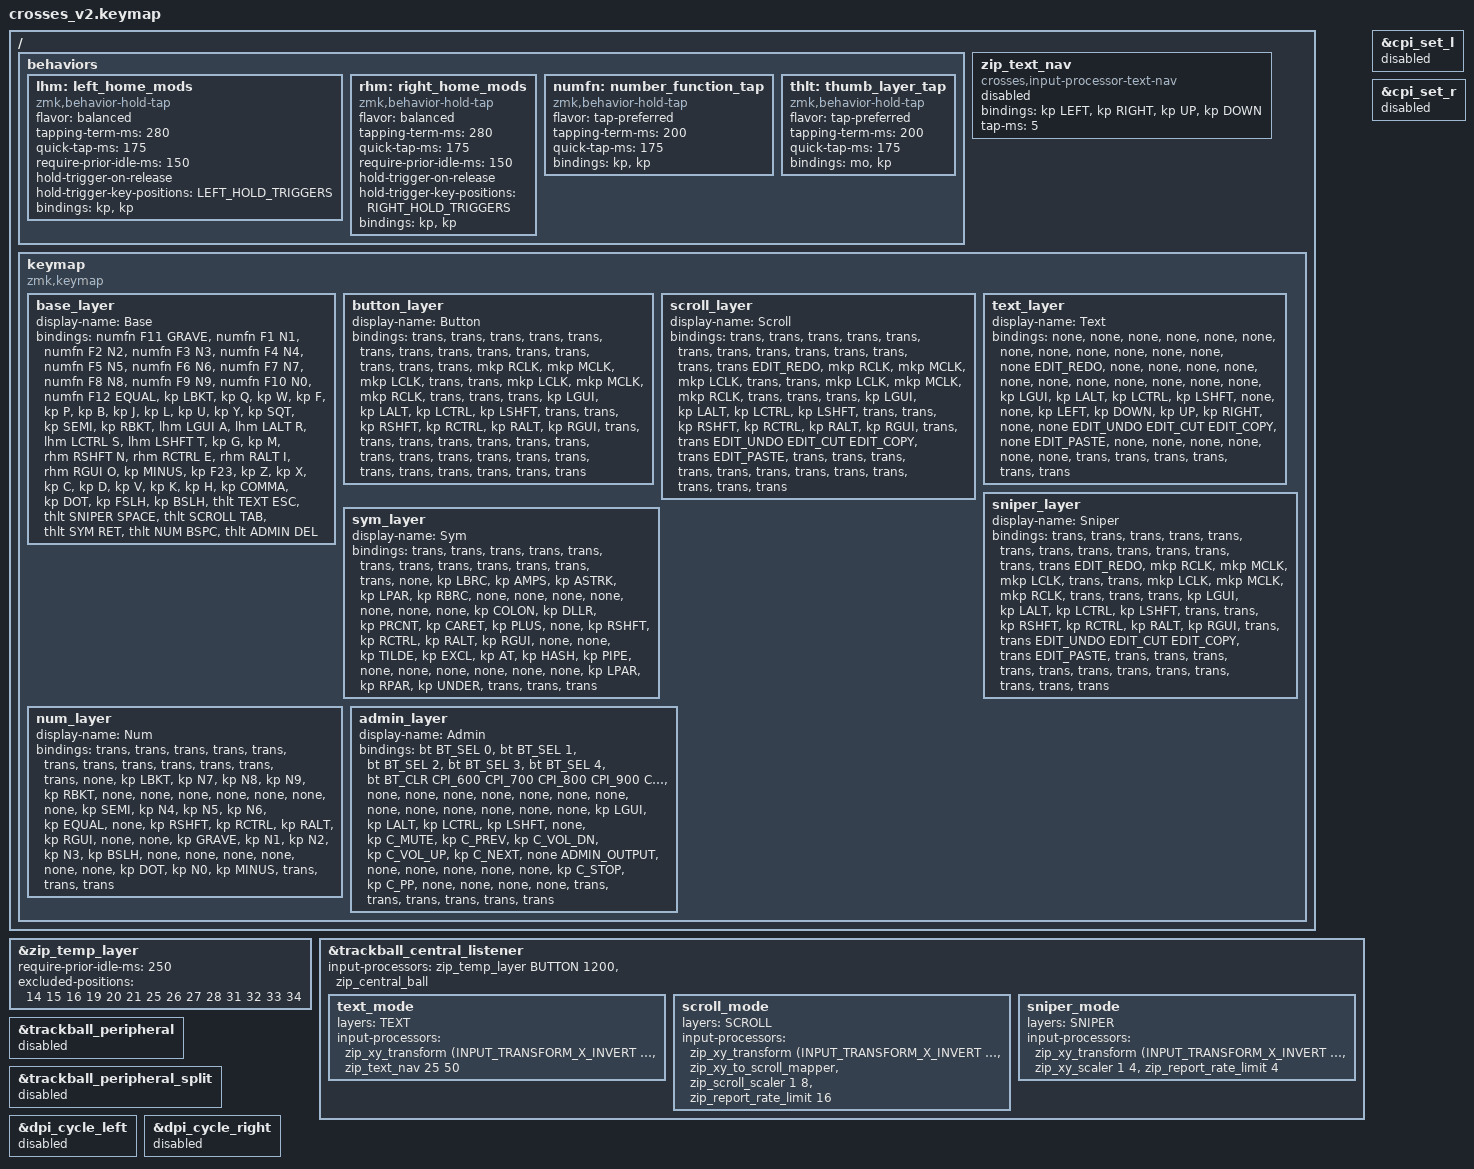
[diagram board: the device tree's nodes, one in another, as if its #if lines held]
#include <behaviors.dtsi>
#include <dt-bindings/zmk/bt.h>
#include <dt-bindings/zmk/input_transform.h>
#include <dt-bindings/zmk/keys.h>
#include <dt-bindings/zmk/outputs.h>
#include <dt-bindings/zmk/pointing.h>

/*
 * Physical positions (54-key layout):
 *   00-11  number row
 *   12-23  top alpha row
 *   24-35  home alpha row
 *   36-47  bottom alpha row
 *   48-53  thumbs
 */

#define BASE    0
#define BUTTON  1
#define SCROLL  2
#define TEXT    3
#define SNIPER  4
#define SYM     5
#define NUM     6
#define ADMIN   7

/* Opposite hand plus all six thumbs. */
#define LEFT_HOLD_TRIGGERS  6 7 8 9 10 11 18 19 20 21 22 23 30 31 32 33 34 35 42 43 44 45 46 47 48 49 50 51 52 53
#define RIGHT_HOLD_TRIGGERS 0 1 2 3 4 5 12 13 14 15 16 17 24 25 26 27 28 29 36 37 38 39 40 41 48 49 50 51 52 53

#define EDIT_REDO  &kp LC(Y)
#define EDIT_UNDO  &kp LC(Z)
#define EDIT_CUT   &kp LC(X)
#define EDIT_COPY  &kp LC(C)
#define EDIT_PASTE &kp LC(V)

/* CPI controls only exist on the right/central firmware. The corresponding
 * physical positions do not exist on the left half anyway. */
#if defined(CROSSES_RIGHT_CONFIG)
#define CPI_600  &cpi_set_r 608 1
#define CPI_700  &cpi_set_r 684 1
#define CPI_800  &cpi_set_r 798 1
#define CPI_900  &cpi_set_r 912 1
#define CPI_1000 &cpi_set_r 988 1
#define CPI_1200 &cpi_set_r 1216 1
#else
#define CPI_600  &none
#define CPI_700  &none
#define CPI_800  &none
#define CPI_900  &none
#define CPI_1000 &none
#define CPI_1200 &none
#endif

#if defined(CROSSES_RIGHT_CONFIG)
#define ADMIN_OUTPUT &out OUT_TOG
#else
#define ADMIN_OUTPUT &none
#endif

/ {
    behaviors {
        /* Urob-style "timeless" positional home-row mod-taps. */
        lhm: left_home_mods {
            compatible = "zmk,behavior-hold-tap";
            #binding-cells = <2>;
            flavor = "balanced";
            tapping-term-ms = <280>;
            quick-tap-ms = <175>;
            require-prior-idle-ms = <150>;
            hold-trigger-on-release;
            hold-trigger-key-positions = <LEFT_HOLD_TRIGGERS>;
            bindings = <&kp>, <&kp>;
        };

        rhm: right_home_mods {
            compatible = "zmk,behavior-hold-tap";
            #binding-cells = <2>;
            flavor = "balanced";
            tapping-term-ms = <280>;
            quick-tap-ms = <175>;
            require-prior-idle-ms = <150>;
            hold-trigger-on-release;
            hold-trigger-key-positions = <RIGHT_HOLD_TRIGGERS>;
            bindings = <&kp>, <&kp>;
        };

        /* Tap for a number-row key (and its shifted symbol), hold for F1-F12. */
        numfn: number_function_tap {
            compatible = "zmk,behavior-hold-tap";
            #binding-cells = <2>;
            flavor = "tap-preferred";
            tapping-term-ms = <200>;
            quick-tap-ms = <175>;
            bindings = <&kp>, <&kp>;
        };

        /* Layer-tap with tap-then-hold support for repeating Backspace/Delete. */
        thlt: thumb_layer_tap {
            compatible = "zmk,behavior-hold-tap";
            #binding-cells = <2>;
            flavor = "tap-preferred";
            tapping-term-ms = <200>;
            quick-tap-ms = <175>;
            bindings = <&mo>, <&kp>;
        };
    };

    /* Horizontal and vertical movement thresholds are passed separately. */
    zip_text_nav: zip_text_nav {
        compatible = "crosses,input-processor-text-nav";
        #input-processor-cells = <2>;
        bindings = <&kp LEFT>, <&kp RIGHT>, <&kp UP>, <&kp DOWN>;
        tap-ms = <5>;
    };

    keymap {
        compatible = "zmk,keymap";

        base_layer {
            display-name = "Base";
            bindings = <
                &numfn F11 GRAVE  &numfn F1 N1  &numfn F2 N2  &numfn F3 N3  &numfn F4 N4  &numfn F5 N5   &numfn F6 N6  &numfn F7 N7  &numfn F8 N8  &numfn F9 N9  &numfn F10 N0  &numfn F12 EQUAL
                &kp LBKT       &kp Q          &kp W          &kp F          &kp P          &kp B           &kp J          &kp L          &kp U          &kp Y           &kp SQT           &kp SEMI
                &kp RBKT       &lhm LGUI A    &lhm LALT R    &lhm LCTRL S   &lhm LSHFT T   &kp G           &kp M          &rhm RSHFT N   &rhm RCTRL E   &rhm RALT I     &rhm RGUI O       &kp MINUS
                &kp F23        &kp Z          &kp X          &kp C          &kp D          &kp V           &kp K          &kp H          &kp COMMA      &kp DOT         &kp FSLH          &kp BSLH
                                                &thlt TEXT ESC  &thlt SNIPER SPACE  &thlt SCROLL TAB   &thlt SYM RET  &thlt NUM BSPC  &thlt ADMIN DEL
            >;
        };

        /* Automatically active after ordinary cursor movement. */
        button_layer {
            display-name = "Button";
            bindings = <
                &trans &trans &trans &trans &trans &trans   &trans &trans &trans &trans &trans &trans
                &trans &trans &mkp RCLK &mkp MCLK &mkp LCLK &trans   &trans &mkp LCLK &mkp MCLK &mkp RCLK &trans &trans
                &trans &kp LGUI &kp LALT &kp LCTRL &kp LSHFT &trans   &trans &kp RSHFT &kp RCTRL &kp RALT &kp RGUI &trans
                &trans &trans &trans &trans &trans &trans   &trans &trans &trans &trans &trans &trans
                                  &trans &trans &trans   &trans &trans &trans
            >;
        };

        scroll_layer {
            display-name = "Scroll";
            bindings = <
                &trans &trans &trans &trans &trans &trans   &trans &trans &trans &trans &trans &trans
                &trans EDIT_REDO &mkp RCLK &mkp MCLK &mkp LCLK &trans   &trans &mkp LCLK &mkp MCLK &mkp RCLK &trans &trans
                &trans &kp LGUI &kp LALT &kp LCTRL &kp LSHFT &trans   &trans &kp RSHFT &kp RCTRL &kp RALT &kp RGUI &trans
                &trans EDIT_UNDO EDIT_CUT EDIT_COPY &trans EDIT_PASTE   &trans &trans &trans &trans &trans &trans
                                  &trans &trans &trans   &trans &trans &trans
            >;
        };

        text_layer {
            display-name = "Text";
            bindings = <
                &none &none &none &none &none &none   &none &none &none &none &none &none
                &none EDIT_REDO &none &none &none &none   &none &none &none &none &none &none
                &none &kp LGUI &kp LALT &kp LCTRL &kp LSHFT &none   &none &kp LEFT &kp DOWN &kp UP &kp RIGHT &none
                &none EDIT_UNDO EDIT_CUT EDIT_COPY &none EDIT_PASTE   &none &none &none &none &none &none
                                  &trans &trans &trans   &trans &trans &trans
            >;
        };

        sniper_layer {
            display-name = "Sniper";
            bindings = <
                &trans &trans &trans &trans &trans &trans   &trans &trans &trans &trans &trans &trans
                &trans EDIT_REDO &mkp RCLK &mkp MCLK &mkp LCLK &trans   &trans &mkp LCLK &mkp MCLK &mkp RCLK &trans &trans
                &trans &kp LGUI &kp LALT &kp LCTRL &kp LSHFT &trans   &trans &kp RSHFT &kp RCTRL &kp RALT &kp RGUI &trans
                &trans EDIT_UNDO EDIT_CUT EDIT_COPY &trans EDIT_PASTE   &trans &trans &trans &trans &trans &trans
                                  &trans &trans &trans   &trans &trans &trans
            >;
        };

        /* Stripped canonical Miryoku symbol core on the left 3x5. */
        sym_layer {
            display-name = "Sym";
            bindings = <
                &trans &trans &trans &trans &trans &trans   &trans &trans &trans &trans &trans &trans
                &none &kp LBRC &kp AMPS &kp ASTRK &kp LPAR &kp RBRC   &none &none &none &none &none &none
                &none &kp COLON &kp DLLR &kp PRCNT &kp CARET &kp PLUS   &none &kp RSHFT &kp RCTRL &kp RALT &kp RGUI &none
                &none &kp TILDE &kp EXCL &kp AT &kp HASH &kp PIPE   &none &none &none &none &none &none
                                  &kp LPAR &kp RPAR &kp UNDER   &trans &trans &trans
            >;
        };

        /* Stripped canonical Miryoku numeric keypad on the left 3x5. */
        num_layer {
            display-name = "Num";
            bindings = <
                &trans &trans &trans &trans &trans &trans   &trans &trans &trans &trans &trans &trans
                &none &kp LBKT &kp N7 &kp N8 &kp N9 &kp RBKT   &none &none &none &none &none &none
                &none &kp SEMI &kp N4 &kp N5 &kp N6 &kp EQUAL   &none &kp RSHFT &kp RCTRL &kp RALT &kp RGUI &none
                &none &kp GRAVE &kp N1 &kp N2 &kp N3 &kp BSLH   &none &none &none &none &none &none
                                  &kp DOT &kp N0 &kp MINUS   &trans &trans &trans
            >;
        };

        admin_layer {
            display-name = "Admin";
            bindings = <
                &bt BT_SEL 0  &bt BT_SEL 1  &bt BT_SEL 2  &bt BT_SEL 3  &bt BT_SEL 4  &bt BT_CLR   CPI_600 CPI_700 CPI_800 CPI_900 CPI_1000 CPI_1200
                &none &none &none &none &none &none   &none &none &none &none &none &none
                &none &kp LGUI &kp LALT &kp LCTRL &kp LSHFT &none   &kp C_MUTE &kp C_PREV &kp C_VOL_DN &kp C_VOL_UP &kp C_NEXT &none
                ADMIN_OUTPUT &none &none &none &none &none   &kp C_STOP &kp C_PP &none &none &none &none
                                  &trans &trans &trans   &trans &trans &trans
            >;
        };
    };
};

/* Automatic click layer while the default cursor pipeline is moving. */
&zip_temp_layer {
    require-prior-idle-ms = <250>;
    /* Six mouse buttons and all eight home-row modifiers remain drag-safe. */
    excluded-positions = <14 15 16 19 20 21 25 26 27 28 31 32 33 34>;
};

&trackball_central_listener {
    input-processors = <&zip_temp_layer BUTTON 1200>, <&zip_central_ball>;

    text_mode {
        layers = <TEXT>;
        input-processors
            = <&zip_xy_transform (INPUT_TRANSFORM_X_INVERT | INPUT_TRANSFORM_Y_INVERT)>
            , <&zip_text_nav 25 50>;
    };

    scroll_mode {
        layers = <SCROLL>;
        input-processors
            = <&zip_xy_transform (INPUT_TRANSFORM_X_INVERT | INPUT_TRANSFORM_Y_INVERT)>
            , <&zip_xy_to_scroll_mapper>
            , <&zip_scroll_scaler 1 8>
            , <&zip_report_rate_limit 16>;
    };

    sniper_mode {
        layers = <SNIPER>;
        input-processors
            = <&zip_xy_transform (INPUT_TRANSFORM_X_INVERT | INPUT_TRANSFORM_Y_INVERT)>
            , <&zip_xy_scaler 1 4>
            , <&zip_report_rate_limit 4>;
    };
};

/* The left sensor is physically absent on this build. */
#if defined(CROSSES_LEFT)
&zip_text_nav {
    status = "disabled";
};

&trackball_peripheral {
    status = "disabled";
};

&trackball_peripheral_split {
    status = "disabled";
};

&dpi_cycle_left { status = "disabled"; };
&dpi_cycle_right { status = "disabled"; };
&cpi_set_l { status = "disabled"; };
&cpi_set_r { status = "disabled"; };
#endif
